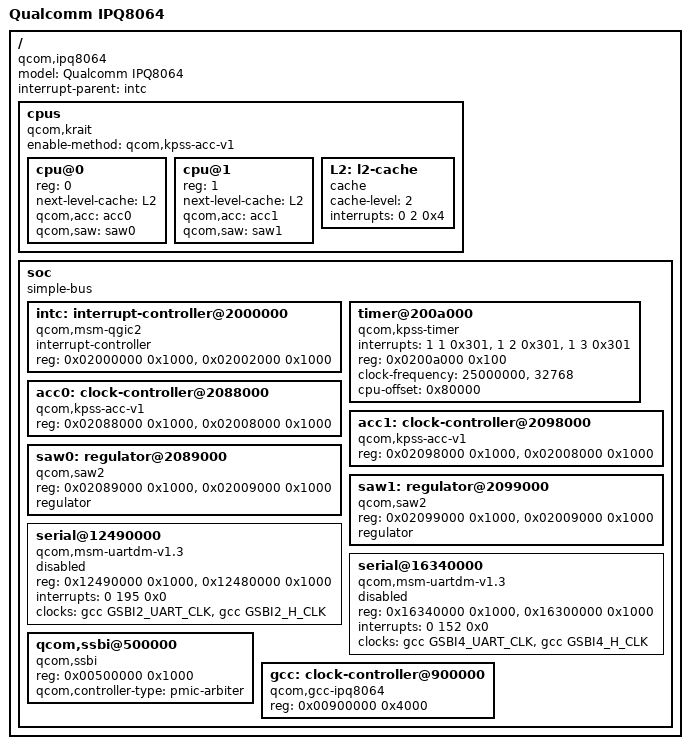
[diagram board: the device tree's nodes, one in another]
/dts-v1/;

/include/ "skeleton.dtsi"

#include <dt-bindings/clock/qcom,gcc-ipq806x.h>

/ {
	model = "Qualcomm IPQ8064";
	compatible = "qcom,ipq8064";
	interrupt-parent = <&intc>;

	cpus {
		#address-cells = <1>;
		#size-cells = <0>;
		compatible = "qcom,krait";
		enable-method = "qcom,kpss-acc-v1";

		cpu@0 {
			device_type = "cpu";
			reg = <0>;
			next-level-cache = <&L2>;
			qcom,acc = <&acc0>;
			qcom,saw = <&saw0>;
		};

		cpu@1 {
			device_type = "cpu";
			reg = <1>;
			next-level-cache = <&L2>;
			qcom,acc = <&acc1>;
			qcom,saw = <&saw1>;
		};

		L2: l2-cache {
			compatible = "cache";
			cache-level = <2>;
			interrupts = <0 2 0x4>;
		};
	};

	soc: soc {
		#address-cells = <1>;
		#size-cells = <1>;
		ranges;
		compatible = "simple-bus";

		intc: interrupt-controller@2000000 {
			compatible = "qcom,msm-qgic2";
			interrupt-controller;
			#interrupt-cells = <3>;
			reg = < 0x02000000 0x1000 >,
			      < 0x02002000 0x1000 >;
		};

		timer@200a000 {
			compatible = "qcom,kpss-timer", "qcom,msm-timer";
			interrupts = <1 1 0x301>,
				     <1 2 0x301>,
				     <1 3 0x301>;
			reg = <0x0200a000 0x100>;
			clock-frequency = <25000000>,
					  <32768>;
			cpu-offset = <0x80000>;
		};

		acc0: clock-controller@2088000 {
			compatible = "qcom,kpss-acc-v1";
			reg = <0x02088000 0x1000>, <0x02008000 0x1000>;
		};

		acc1: clock-controller@2098000 {
			compatible = "qcom,kpss-acc-v1";
			reg = <0x02098000 0x1000>, <0x02008000 0x1000>;
		};

		saw0: regulator@2089000 {
			compatible = "qcom,saw2";
			reg = <0x02089000 0x1000>, <0x02009000 0x1000>;
			regulator;
		};

		saw1: regulator@2099000 {
			compatible = "qcom,saw2";
			reg = <0x02099000 0x1000>, <0x02009000 0x1000>;
			regulator;
		};

		serial@12490000 {
			compatible = "qcom,msm-uartdm-v1.3", "qcom,msm-uartdm";
			reg = <0x12490000 0x1000>,
			      <0x12480000 0x1000>;
			interrupts = <0 195 0x0>;
			clocks = <&gcc GSBI2_UART_CLK>, <&gcc GSBI2_H_CLK>;
			clock-names = "core", "iface";
			status = "disabled";
		};

		serial@16340000 {
			compatible = "qcom,msm-uartdm-v1.3", "qcom,msm-uartdm";
			reg = <0x16340000 0x1000>,
			      <0x16300000 0x1000>;
			interrupts = <0 152 0x0>;
			clocks = <&gcc GSBI4_UART_CLK>, <&gcc GSBI4_H_CLK>;
			clock-names = "core", "iface";
			status = "disabled";
		};

		qcom,ssbi@500000 {
			compatible = "qcom,ssbi";
			reg = <0x00500000 0x1000>;
			qcom,controller-type = "pmic-arbiter";
		};

		gcc: clock-controller@900000 {
			compatible = "qcom,gcc-ipq8064";
			reg = <0x00900000 0x4000>;
			#clock-cells = <1>;
			#reset-cells = <1>;
		};
	};
};
